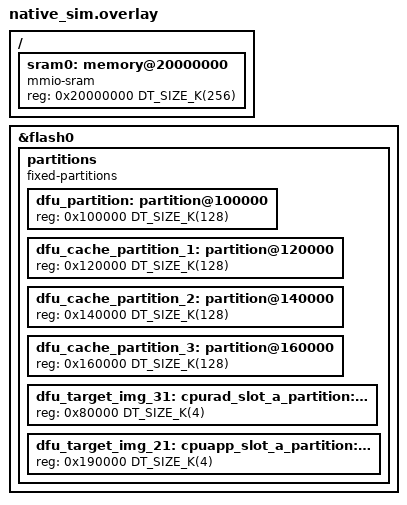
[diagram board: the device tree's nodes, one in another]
/*
 * Copyright (c) 2024 Nordic Semiconductor ASA
 *
 * SPDX-License-Identifier: LicenseRef-Nordic-5-Clause
 */

&flash0 {
	partitions {
		compatible = "fixed-partitions";
		#address-cells = < 0x1 >;
		#size-cells = < 0x1 >;

		dfu_partition: partition@100000 {
			reg = < 0x100000 DT_SIZE_K(128) >;
		};

		dfu_cache_partition_1: partition@120000 {
			reg = <0x120000 DT_SIZE_K(128)>;
		};

		dfu_cache_partition_2: partition@140000 {
			reg = <0x140000 DT_SIZE_K(128)>;
		};

		dfu_cache_partition_3: partition@160000 {
			reg = <0x160000 DT_SIZE_K(128)>;
		};

		dfu_target_img_31: cpurad_slot_a_partition: partition@80000 {
			reg = <0x80000 DT_SIZE_K(4)>;
		};

		dfu_target_img_21: cpuapp_slot_a_partition: partition@190000 {
			reg = <0x190000 DT_SIZE_K(4)>;
		};
	};
};

/ {
	sram0: memory@20000000 {
		compatible = "mmio-sram";
		reg = <0x20000000 DT_SIZE_K(256)>;
	};
};
